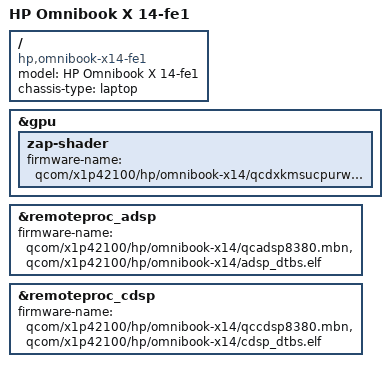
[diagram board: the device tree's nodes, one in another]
// SPDX-License-Identifier: BSD-3-Clause
/*
 * Copyright (c) 2023 Qualcomm Innovation Center, Inc. All rights reserved.
 */

/dts-v1/;

#include "x1p42100.dtsi"
#include "x1e80100-pmics.dtsi"
#include "x1-hp-omnibook-x14.dtsi"
/delete-node/ &pmc8380_6;
/delete-node/ &pmc8380_6_thermal;

/ {
	model = "HP Omnibook X 14-fe1";
	compatible = "hp,omnibook-x14-fe1", "qcom,x1p42100";
	chassis-type = "laptop";
};

&gpu {
	status = "okay";

	zap-shader {
		firmware-name = "qcom/x1p42100/hp/omnibook-x14/qcdxkmsucpurwa.mbn";
	};
};

&remoteproc_adsp {
	firmware-name = "qcom/x1p42100/hp/omnibook-x14/qcadsp8380.mbn",
			"qcom/x1p42100/hp/omnibook-x14/adsp_dtbs.elf";

	status = "okay";
};

&remoteproc_cdsp {
	firmware-name = "qcom/x1p42100/hp/omnibook-x14/qccdsp8380.mbn",
			"qcom/x1p42100/hp/omnibook-x14/cdsp_dtbs.elf";

	status = "okay";
};
